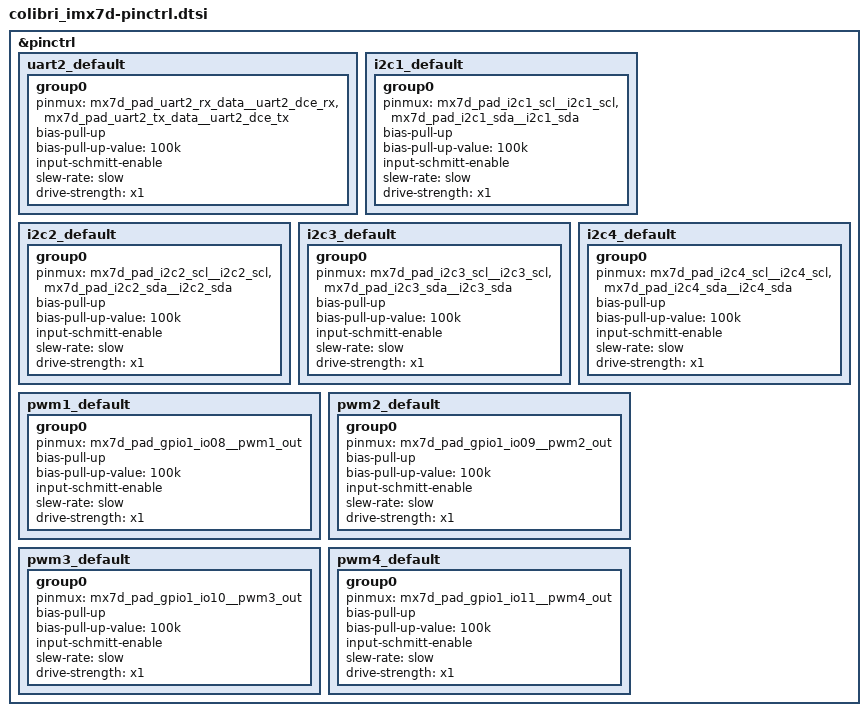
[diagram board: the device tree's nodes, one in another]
/*
 * Copyright (c) 2017,2019 NXP
 *
 * SPDX-License-Identifier: Apache-2.0
 */

#include <nxp/nxp_imx/mimx7d-pinctrl.dtsi>

&pinctrl {
	uart2_default: uart2_default {
		group0 {
			pinmux = <&mx7d_pad_uart2_rx_data__uart2_dce_rx>,
				<&mx7d_pad_uart2_tx_data__uart2_dce_tx>;
			bias-pull-up;
			bias-pull-up-value = "100k";
			input-schmitt-enable;
			slew-rate = "slow";
			drive-strength = "x1";
		};
	};

	i2c1_default: i2c1_default {
		group0 {
			pinmux = <&mx7d_pad_i2c1_scl__i2c1_scl>,
				<&mx7d_pad_i2c1_sda__i2c1_sda>;
			bias-pull-up;
			bias-pull-up-value = "100k";
			input-schmitt-enable;
			slew-rate = "slow";
			drive-strength = "x1";
		};
	};

	i2c2_default: i2c2_default {
		group0 {
			pinmux = <&mx7d_pad_i2c2_scl__i2c2_scl>,
				<&mx7d_pad_i2c2_sda__i2c2_sda>;
			bias-pull-up;
			bias-pull-up-value = "100k";
			input-schmitt-enable;
			slew-rate = "slow";
			drive-strength = "x1";
		};
	};

	i2c3_default: i2c3_default {
		group0 {
			pinmux = <&mx7d_pad_i2c3_scl__i2c3_scl>,
				<&mx7d_pad_i2c3_sda__i2c3_sda>;
			bias-pull-up;
			bias-pull-up-value = "100k";
			input-schmitt-enable;
			slew-rate = "slow";
			drive-strength = "x1";
		};
	};

	i2c4_default: i2c4_default {
		group0 {
			pinmux = <&mx7d_pad_i2c4_scl__i2c4_scl>,
				<&mx7d_pad_i2c4_sda__i2c4_sda>;
			bias-pull-up;
			bias-pull-up-value = "100k";
			input-schmitt-enable;
			slew-rate = "slow";
			drive-strength = "x1";
		};
	};

	pwm1_default: pwm1_default {
		group0 {
			pinmux = <&mx7d_pad_gpio1_io08__pwm1_out>;
			bias-pull-up;
			bias-pull-up-value = "100k";
			input-schmitt-enable;
			slew-rate = "slow";
			drive-strength = "x1";
		};
	};

	pwm2_default: pwm2_default {
		group0 {
			pinmux = <&mx7d_pad_gpio1_io09__pwm2_out>;
			bias-pull-up;
			bias-pull-up-value = "100k";
			input-schmitt-enable;
			slew-rate = "slow";
			drive-strength = "x1";
		};
	};

	pwm3_default: pwm3_default {
		group0 {
			pinmux = <&mx7d_pad_gpio1_io10__pwm3_out>;
			bias-pull-up;
			bias-pull-up-value = "100k";
			input-schmitt-enable;
			slew-rate = "slow";
			drive-strength = "x1";
		};
	};

	pwm4_default: pwm4_default {
		group0 {
			pinmux = <&mx7d_pad_gpio1_io11__pwm4_out>;
			bias-pull-up;
			bias-pull-up-value = "100k";
			input-schmitt-enable;
			slew-rate = "slow";
			drive-strength = "x1";
		};
	};

};
